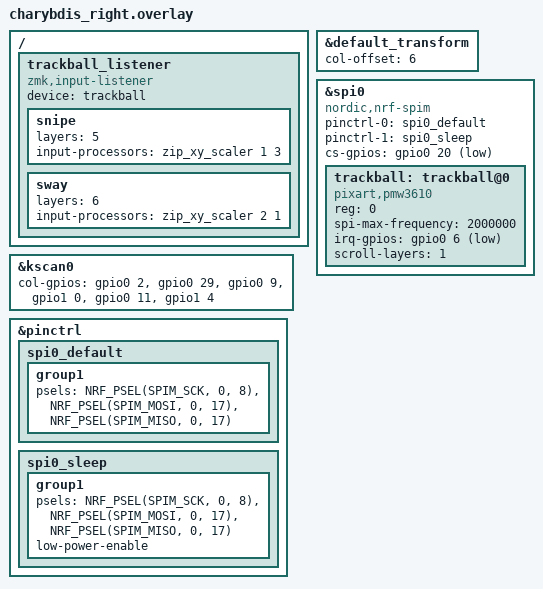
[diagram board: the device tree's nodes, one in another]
/*
 * Copyright (c) 2020 ZMK Contributors
 *
 * SPDX-License-Identifier: MIT
 */
 
#include "charybdis.dtsi"

&default_transform {
    col-offset = <6>;
}; 

&kscan0 {
	col-gpios
		= <&gpio0 2 (GPIO_ACTIVE_HIGH | GPIO_PULL_DOWN)>
		, <&gpio0 29 (GPIO_ACTIVE_HIGH | GPIO_PULL_DOWN)>
		, <&gpio0 9 (GPIO_ACTIVE_HIGH | GPIO_PULL_DOWN)>
		, <&gpio1 0  (GPIO_ACTIVE_HIGH | GPIO_PULL_DOWN)>
		, <&gpio0 11 (GPIO_ACTIVE_HIGH | GPIO_PULL_DOWN)>
		, <&gpio1 4  (GPIO_ACTIVE_HIGH | GPIO_PULL_DOWN)>
		;
};

// trackball bus
&pinctrl {
    spi0_default: spi0_default {
        group1 {
            psels = <NRF_PSEL(SPIM_SCK, 0, 8)>,
                <NRF_PSEL(SPIM_MOSI, 0, 17)>,
                <NRF_PSEL(SPIM_MISO, 0, 17)>;
        };
    };

    spi0_sleep: spi0_sleep {
        group1 {
            psels = <NRF_PSEL(SPIM_SCK, 0, 8)>,
                <NRF_PSEL(SPIM_MOSI, 0, 17)>,
                <NRF_PSEL(SPIM_MISO, 0, 17)>;
            low-power-enable;
        };
    };
};

&spi0 {
    status = "okay";
    compatible = "nordic,nrf-spim";
    pinctrl-0 = <&spi0_default>;
    pinctrl-1 = <&spi0_sleep>;
    pinctrl-names = "default", "sleep";
    cs-gpios = <&gpio0 20 GPIO_ACTIVE_LOW>;

    trackball: trackball@0 {
        status = "okay";
        compatible = "pixart,pmw3610";
        reg = <0>;
        spi-max-frequency = <2000000>;
        irq-gpios = <&gpio0 6 (GPIO_ACTIVE_LOW | GPIO_PULL_UP)>;
        scroll-layers = <1>;
        //snipe-layers = <2>;
      // automouse-layer = <3>;
    };
};


//RGB bus




/ {
    /*
     * SNIPE / SWAY — scale the physical trackball's pointer movement.
     * Per-layer overrides on the trackball's input listener: while the snipe or
     * sway layer is active (held via the k+l / j+k combos in charybdis.keymap),
     * the matching scaler is applied to the trackball's X/Y before it becomes
     * HID movement:
     *   - snipe: x1/3 -> slower & precise (e.g. selecting text)
     *   - sway:  x2/1 -> faster, to cross the screen quickly
     * zip_xy_scaler tracks remainders so sub-step motion isn't lost. Pointer
     * only (scrolling is unaffected). Tune the <mult div> pairs to taste.
     *
     * Defined here, not in the keymap, because the trackball only exists on the
     * right half while the keymap is shared by both halves. The layer numbers
     * must stay in sync with SNIPE_LAYER (5) / SWAY_LAYER (6) in charybdis.keymap.
     * (&zip_xy_scaler comes from <input/processors.dtsi>, included by the keymap.)
     */
    trackball_listener: trackball_listener {
        compatible = "zmk,input-listener";
        device = <&trackball>;

        snipe {
            layers = <5>;   // SNIPE_LAYER in charybdis.keymap
            input-processors = <&zip_xy_scaler 1 3>;
        };

        sway {
            layers = <6>;   // SWAY_LAYER in charybdis.keymap
            input-processors = <&zip_xy_scaler 2 1>;
        };
    };
};


